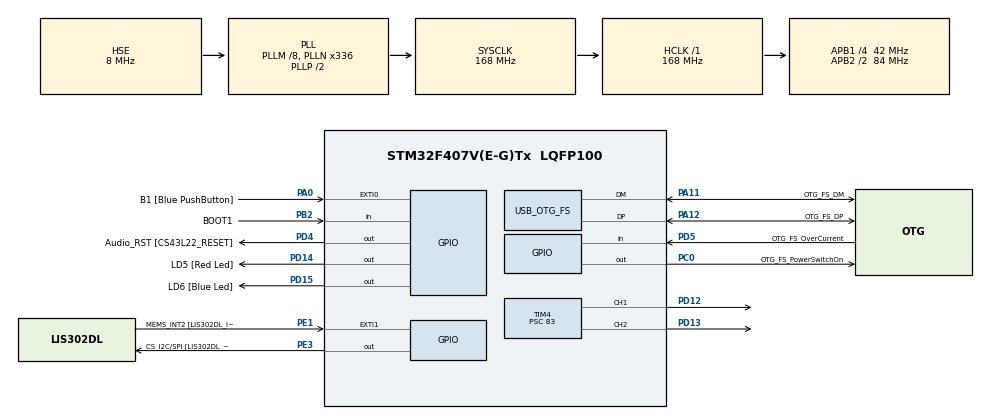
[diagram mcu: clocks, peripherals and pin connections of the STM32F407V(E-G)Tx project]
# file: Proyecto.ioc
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ADC1.Channel-0\#ChannelRegularConversion=ADC_CHANNEL_TEMPSENSOR
ADC1.NbrOfConversionFlag=1
ADC1.Rank-0\#ChannelRegularConversion=1
ADC1.SamplingTime-0\#ChannelRegularConversion=ADC_SAMPLETIME_3CYCLES
ADC1.master=1
Mcu.Family=STM32F4
Mcu.Name=STM32F407V(E-G)Tx
Mcu.Package=LQFP100
NVIC.EXTI0_IRQn=true\:0\:2\:false\:false\:true\:true\:true\:true
NVIC.OTG_FS_IRQn=true\:0\:0\:false\:false\:true\:false\:true\:true
NVIC.PriorityGroup=NVIC_PRIORITYGROUP_0
NVIC.TIM2_IRQn=true\:0\:1\:true\:false\:true\:true\:true\:true
PA0-WKUP.GPIO_Label=B1 [Blue PushButton]
PA0-WKUP.GPIO_ModeDefaultEXTI=GPIO_MODE_IT_RISING
PA0-WKUP.GPIO_PuPd=GPIO_NOPULL
PA0-WKUP.Signal=GPXTI0
PA10.GPIO_Label=OTG_FS_ID
PA10.GPIO_Mode=GPIO_MODE_AF_PP
PA10.GPIO_PuPd=GPIO_NOPULL
PA10.GPIO_Speed=GPIO_SPEED_FREQ_LOW
PA10.Signal=USB_OTG_FS_ID
PA11.GPIO_Label=OTG_FS_DM
PA11.GPIO_Mode=GPIO_MODE_AF_PP
PA11.GPIO_PuPd=GPIO_NOPULL
PA11.GPIO_Speed=GPIO_SPEED_FREQ_LOW
PA11.Mode=Device_Only
PA11.Signal=USB_OTG_FS_DM
PA12.GPIO_Label=OTG_FS_DP
PA12.GPIO_Mode=GPIO_MODE_AF_PP
PA12.GPIO_PuPd=GPIO_NOPULL
PA12.GPIO_Speed=GPIO_SPEED_FREQ_LOW
PA12.Mode=Device_Only
PA12.Signal=USB_OTG_FS_DP
PA13.GPIO_Label=SWDIO
PA13.Mode=Serial_Wire
PA13.Signal=SYS_JTMS-SWDIO
PA14.GPIO_Label=SWCLK
PA14.Mode=Serial_Wire
PA14.Signal=SYS_JTCK-SWCLK
PA4.GPIO_Label=I2S3_WS [CS43L22_LRCK]
PA4.GPIO_Mode=GPIO_MODE_AF_PP
PA4.GPIO_PuPd=GPIO_NOPULL
PA4.GPIO_Speed=GPIO_SPEED_FREQ_LOW
PA4.Signal=I2S3_WS
PA5.GPIO_Label=SPI1_SCK [LIS302DL_SCL/SPC]
PA5.GPIO_Mode=GPIO_MODE_AF_PP
PA5.GPIO_PuPd=GPIO_NOPULL
PA5.GPIO_Speed=GPIO_SPEED_FREQ_LOW
PA5.Signal=SPI1_SCK
PA6.GPIO_Label=SPI1_MISO [LIS302DL_SDO]
PA6.GPIO_Mode=GPIO_MODE_AF_PP
PA6.GPIO_PuPd=GPIO_NOPULL
PA6.GPIO_Speed=GPIO_SPEED_FREQ_LOW
PA6.Signal=SPI1_MISO
PA7.GPIO_Label=SPI1_MOSI [LIS302DL_SDA/SDI/SDO]
PA7.GPIO_Mode=GPIO_MODE_AF_PP
PA7.GPIO_PuPd=GPIO_NOPULL
PA7.GPIO_Speed=GPIO_SPEED_FREQ_LOW
PA7.Signal=SPI1_MOSI
PA9.GPIO_Label=VBUS_FS
PA9.GPIO_Mode=GPIO_MODE_INPUT
PA9.GPIO_PuPd=GPIO_NOPULL
PA9.Signal=USB_OTG_FS_VBUS
PB10.GPIO_Label=CLK_IN [MP45DT02_CLK]
PB10.GPIO_Mode=GPIO_MODE_AF_PP
PB10.GPIO_PuPd=GPIO_NOPULL
PB10.GPIO_Speed=GPIO_SPEED_FREQ_LOW
PB10.Signal=I2S2_CK
PB2.GPIO_Label=BOOT1
PB2.GPIO_Mode=GPIO_MODE_INPUT
PB2.GPIO_PuPd=GPIO_NOPULL
PB2.Signal=GPIO_Input
PB3.GPIO_Label=SWO
PB3.Signal=SYS_JTDO-SWO
PB6.GPIO_Label=Audio_SCL [CS43L22_SCL]
PB6.GPIO_Mode=GPIO_MODE_AF_OD
PB6.GPIO_Pu=GPIO_PULLUP
PB6.GPIO_PuPd=GPIO_NOPULL
PB6.GPIO_Speed=GPIO_SPEED_FREQ_LOW
PB6.Signal=I2C1_SCL
PB9.GPIO_Label=Audio_SDA [CS43L22_SDA]
PB9.GPIO_Mode=GPIO_MODE_AF_OD
PB9.GPIO_Pu=GPIO_PULLUP
PB9.GPIO_PuPd=GPIO_NOPULL
PB9.GPIO_Speed=GPIO_SPEED_FREQ_LOW
PB9.Signal=I2C1_SDA
PC0.GPIO_Label=OTG_FS_PowerSwitchOn
PC0.GPIO_PuPd=GPIO_NOPULL
PC0.GPIO_Speed=GPIO_SPEED_FREQ_LOW
PC0.PinState=GPIO_PIN_SET
PC0.Signal=GPIO_Output
PC10.GPIO_Label=I2S3_SCK [CS43L22_SCLK]
PC10.GPIO_Mode=GPIO_MODE_AF_PP
PC10.GPIO_PuPd=GPIO_NOPULL
PC10.GPIO_Speed=GPIO_SPEED_FREQ_LOW
PC10.Signal=I2S3_CK
PC12.GPIO_Label=I2S3_SD [CS43L22_SDIN]
PC12.GPIO_Mode=GPIO_MODE_AF_PP
PC12.GPIO_PuPd=GPIO_NOPULL
PC12.GPIO_Speed=GPIO_SPEED_FREQ_LOW
PC12.Signal=I2S3_SD
PC14-OSC32_IN.GPIO_Label=PC14-OSC32_IN
PC14-OSC32_IN.Mode=LSE-External-Oscillator
PC14-OSC32_IN.Signal=RCC_OSC32_IN
PC15-OSC32_OUT.GPIO_Label=PC15-OSC32_OUT
PC15-OSC32_OUT.Mode=LSE-External-Oscillator
PC15-OSC32_OUT.Signal=RCC_OSC32_OUT
PC3.GPIO_Label=PDM_OUT [MP45DT02_DOUT]
PC3.GPIO_Mode=GPIO_MODE_AF_PP
PC3.GPIO_PuPd=GPIO_NOPULL
PC3.GPIO_Speed=GPIO_SPEED_FREQ_LOW
PC3.Signal=I2S2_SD
PC7.GPIO_Label=I2S3_MCK [CS43L22_MCLK]
PC7.GPIO_Mode=GPIO_MODE_AF_PP
PC7.GPIO_PuPd=GPIO_NOPULL
PC7.GPIO_Speed=GPIO_SPEED_FREQ_LOW
PC7.Signal=I2S3_MCK
PD12.Signal=S_TIM4_CH1
PD13.Signal=S_TIM4_CH2
PD14.GPIO_Label=LD5 [Red Led]
PD14.GPIO_PuPd=GPIO_NOPULL
PD14.GPIO_Speed=GPIO_SPEED_FREQ_LOW
PD14.Signal=GPIO_Output
PD15.GPIO_Label=LD6 [Blue Led]
PD15.GPIO_PuPd=GPIO_NOPULL
PD15.GPIO_Speed=GPIO_SPEED_FREQ_LOW
PD15.Signal=GPIO_Output
PD4.GPIO_Label=Audio_RST [CS43L22_RESET]
PD4.GPIO_PuPd=GPIO_NOPULL
PD4.GPIO_Speed=GPIO_SPEED_FREQ_LOW
PD4.Signal=GPIO_Output
PD5.GPIO_Label=OTG_FS_OverCurrent
PD5.GPIO_Mode=GPIO_MODE_INPUT
PD5.GPIO_PuPd=GPIO_NOPULL
PD5.Signal=GPIO_Input
PE1.GPIO_Label=MEMS_INT2 [LIS302DL_INT2]
PE1.GPIO_ModeDefaultEXTI=GPIO_MODE_EVT_RISING
PE1.GPIO_PuPd=GPIO_NOPULL
PE1.Signal=GPXTI1
PE3.GPIO_Label=CS_I2C/SPI [LIS302DL_CS_I2C/SPI]
PE3.GPIO_PuPd=GPIO_NOPULL
PE3.GPIO_Speed=GPIO_SPEED_FREQ_LOW
PE3.Signal=GPIO_Output
PH0-OSC_IN.GPIO_Label=PH0-OSC_IN
PH0-OSC_IN.Mode=HSE-External-Oscillator
PH0-OSC_IN.Signal=RCC_OSC_IN
PH1-OSC_OUT.GPIO_Label=PH1-OSC_OUT
PH1-OSC_OUT.Mode=HSE-External-Oscillator
PH1-OSC_OUT.Signal=RCC_OSC_OUT
ProjectManager.HeapSize=0x200
ProjectManager.StackSize=0x400
ProjectManager.TargetToolchain=STM32CubeIDE
RCC.48MHZClocksFreq_Value=48000000
RCC.AHBFreq_Value=168000000
RCC.APB1CLKDivider=RCC_HCLK_DIV4
RCC.APB1Freq_Value=42000000
RCC.APB1TimFreq_Value=84000000
RCC.APB2CLKDivider=RCC_HCLK_DIV2
RCC.APB2Freq_Value=84000000
RCC.APB2TimFreq_Value=168000000
RCC.CortexFreq_Value=168000000
RCC.HCLKFreq_Value=168000000
RCC.HSE_VALUE=8000000
RCC.HSI_VALUE=16000000
RCC.PLLM=8
RCC.PLLN=336
RCC.PLLQ=7
RCC.SYSCLKFreq_VALUE=168000000
RCC.SYSCLKSource=RCC_SYSCLKSOURCE_PLLCLK
RCC.VCOOutputFreq_Value=336000000
SH.S_TIM4_CH1.0=TIM4_CH1,PWM Generation1 CH1
SH.S_TIM4_CH2.0=TIM4_CH2,PWM Generation2 CH2
TIM2.Period=99
TIM2.Prescaler=8399
TIM4.Channel-PWM\ Generation1\ CH1=TIM_CHANNEL_1
TIM4.Channel-PWM\ Generation2\ CH2=TIM_CHANNEL_2
TIM4.Period=999
TIM4.Prescaler=83
USB_DEVICE.CLASS_NAME_FS=CDC
USB_DEVICE.VirtualMode-CDC_FS=Cdc
USB_DEVICE.VirtualModeFS=Cdc_FS
USB_OTG_FS.VirtualMode=Device_Only
VP_ADC1_TempSens_Input.Mode=IN-TempSens
VP_TIM2_VS_ClockSourceINT.Mode=Internal
VP_TIM4_VS_ClockSourceINT.Mode=Internal
VP_USB_DEVICE_VS_USB_DEVICE_CDC_FS.Mode=CDC_FS
board=STM32F407G-DISC1

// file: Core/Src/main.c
/* USER CODE BEGIN Header */
/**
  ******************************************************************************
  * @file           : main.c
  * @brief          : Main program body
  ******************************************************************************
  * @attention
  *
  * Copyright (c) 2026 STMicroelectronics.
  * All rights reserved.
  *
  * This software is licensed under terms that can be found in the LICENSE file
  * in the root directory of this software component.
  * If no LICENSE file comes with this software, it is provided AS-IS.
  *
  ******************************************************************************
  */
/* USER CODE END Header */
#include "main.h"
#include "usb_device.h"
#include "usbd_cdc_if.h"
#include "bottler.h"

void MaquinaEstados(void);

ADC_HandleTypeDef hadc1;

TIM_HandleTypeDef htim2;
TIM_HandleTypeDef htim4;

void SystemClock_Config(void);
static void MX_GPIO_Init(void);
static void MX_TIM2_Init(void);
static void MX_TIM4_Init(void);
static void MX_ADC1_Init(void);

/* USER CODE BEGIN 0 */
volatile uint8_t presencia = 0;
volatile uint8_t contador = 0;
volatile uint8_t emergencia=0;
volatile uint8_t turno_usb=0; //0 envia temperatura y 1 envia estado
extern volatile uint8_t estado_anterior;
volatile uint32_t ultimo_envio = 0;
extern volatile uint8_t estado;
extern volatile float temp_actual;

/* USER CODE END 0 */

int main(void)
{

  /* USER CODE BEGIN 1 */
//  Definimso el comienzo //

  /* USER CODE END 1 */

  /* MCU Configuration--------------------------------------------------------*/

  /* Reset of all peripherals, Initializes the Flash interface and the Systick. */
  HAL_Init();

  /* Configure the system clock */
  SystemClock_Config();

  /* Initialize all configured peripherals */
  MX_GPIO_Init();
  MX_TIM2_Init();
  MX_TIM4_Init();
  MX_USB_DEVICE_Init();
  MX_ADC1_Init();
  /* USER CODE BEGIN 2 */
  bottlerInit();

  HAL_TIM_Base_Start_IT(&htim2);

  /* USER CODE END 2 */

  /* Infinite loop */
  while (1)
  {
	  MaquinaEstados();

		if ((turno_usb==0)&&(HAL_GetTick() - ultimo_envio > 100)) { //Comprobamos que haya pasado medio segundo desde el ultimo envio
		    temp_actual = getTemperature();

		    int ent = (int)temp_actual;
		    int dec = (int)((temp_actual - ent) * 10);
		    //Como la placa no trae activado el %f por defecto para ganar memoria, obtenemos las unidades y decimales cono enteros.
	        // obtenemos las unidades y decimales tratándolos matemáticamente como enteros.

		    char msg_temp[20];
		    sprintf(msg_temp, "T:%d.%d\r\n", ent, dec);
		    //Formateamos una cadena de caracteres como T:(ent).(dec)\r\n
		    //Añadimos \r\n (salto de línea) al final para que el SCADA en Qt sepa exactamente dónde termina el mensaje al usar readLine().
		    CDC_Transmit_FS((uint8_t*)msg_temp, strlen(msg_temp)); //Transmitimos la cadena de texto a la interfaz.

		    turno_usb=0;

		    ultimo_envio = HAL_GetTick(); //Obtenemos el momento en el que se ha realizado el ultimo envío.
		    //HAL_GetTick() es una funcion que nos dice cuanto tiempo ha estado encendido el Stm32.

		}

		if ((turno_usb==1)&&(HAL_GetTick() - ultimo_envio > 100)) { //Comprobamos que haya pasado medio segundo desde el ultimo envio

			//Forzamos el envío del estado actual de forma periódica así nuestra interfaz se entera del estado real aunque arranque tarde.
			char msg_est[20];//Declaramos y definimos una cadena de caracteres vacia que se reseteará cada vez que el superloop llame a la maquina de estados.
			sprintf(msg_est, "%d\r\n", estado); //Escribimos nuestro estado por encima de los caracteres vacios de la cadena.
			CDC_Transmit_FS((uint8_t*)msg_est, strlen(msg_est));//Transmitimos la cadena de texto a la interfaz.
			//Un problema que teniamos es que si arrancabamos la interfaz un rato despues del programa se quedaba colgada en el estado 0
			//Aunque estuviese por ejemplo en emergencia hasta que cambiaba de estado, metiendo esta actualizacion periodica siempre sabremos donde esta.

			turno_usb=0;

			ultimo_envio = HAL_GetTick(); //Obtenemos el momento en el que se ha realizado el ultimo envío.
			//HAL_GetTick() es una funcion que nos dice cuanto tiempo ha estado encendido el Stm32.
		}

  }
}

void SystemClock_Config(void)
{
  RCC_OscInitTypeDef RCC_OscInitStruct = {0};
  RCC_ClkInitTypeDef RCC_ClkInitStruct = {0};

  /** Configure the main internal regulator output voltage
  */
  __HAL_RCC_PWR_CLK_ENABLE();
  __HAL_PWR_VOLTAGESCALING_CONFIG(PWR_REGULATOR_VOLTAGE_SCALE1);

  /** Initializes the RCC Oscillators according to the specified parameters
  * in the RCC_OscInitTypeDef structure.
  */
  RCC_OscInitStruct.OscillatorType = RCC_OSCILLATORTYPE_HSE;
  RCC_OscInitStruct.HSEState = RCC_HSE_ON;
  RCC_OscInitStruct.PLL.PLLState = RCC_PLL_ON;
  RCC_OscInitStruct.PLL.PLLSource = RCC_PLLSOURCE_HSE;
  RCC_OscInitStruct.PLL.PLLM = 8;
  RCC_OscInitStruct.PLL.PLLN = 336;
  RCC_OscInitStruct.PLL.PLLP = RCC_PLLP_DIV2;
  RCC_OscInitStruct.PLL.PLLQ = 7;
  if (HAL_RCC_OscConfig(&RCC_OscInitStruct) != HAL_OK)
  {
    Error_Handler();
  }

  /** Initializes the CPU, AHB and APB buses clocks
  */
  RCC_ClkInitStruct.ClockType = RCC_CLOCKTYPE_HCLK|RCC_CLOCKTYPE_SYSCLK
                              |RCC_CLOCKTYPE_PCLK1|RCC_CLOCKTYPE_PCLK2;
  RCC_ClkInitStruct.SYSCLKSource = RCC_SYSCLKSOURCE_PLLCLK;
  RCC_ClkInitStruct.AHBCLKDivider = RCC_SYSCLK_DIV1;
  RCC_ClkInitStruct.APB1CLKDivider = RCC_HCLK_DIV4;
  RCC_ClkInitStruct.APB2CLKDivider = RCC_HCLK_DIV2;

  if (HAL_RCC_ClockConfig(&RCC_ClkInitStruct, FLASH_LATENCY_5) != HAL_OK)
  {
    Error_Handler();
  }
}

static void MX_ADC1_Init(void)
{

  ADC_ChannelConfTypeDef sConfig = {0};

  /** Configure the global features of the ADC (Clock, Resolution, Data Alignment and number of conversion)
  */
  hadc1.Instance = ADC1;
  hadc1.Init.ClockPrescaler = ADC_CLOCK_SYNC_PCLK_DIV4;
  hadc1.Init.Resolution = ADC_RESOLUTION_12B;
  hadc1.Init.ScanConvMode = DISABLE;
  hadc1.Init.ContinuousConvMode = DISABLE;
  hadc1.Init.DiscontinuousConvMode = DISABLE;
  hadc1.Init.ExternalTrigConvEdge = ADC_EXTERNALTRIGCONVEDGE_NONE;
  hadc1.Init.ExternalTrigConv = ADC_SOFTWARE_START;
  hadc1.Init.DataAlign = ADC_DATAALIGN_RIGHT;
  hadc1.Init.NbrOfConversion = 1;
  hadc1.Init.DMAContinuousRequests = DISABLE;
  hadc1.Init.EOCSelection = ADC_EOC_SINGLE_CONV;
  if (HAL_ADC_Init(&hadc1) != HAL_OK)
  {
    Error_Handler();
  }

  /** Configure for the selected ADC regular channel its corresponding rank in the sequencer and its sample time.
  */
  sConfig.Channel = ADC_CHANNEL_TEMPSENSOR;
  sConfig.Rank = 1;
  sConfig.SamplingTime = ADC_SAMPLETIME_3CYCLES;
  if (HAL_ADC_ConfigChannel(&hadc1, &sConfig) != HAL_OK)
  {
    Error_Handler();
  }

}

static void MX_TIM2_Init(void)
{

  TIM_ClockConfigTypeDef sClockSourceConfig = {0};
  TIM_MasterConfigTypeDef sMasterConfig = {0};

  htim2.Instance = TIM2;
  htim2.Init.Prescaler = 8399;
  htim2.Init.CounterMode = TIM_COUNTERMODE_UP;
  htim2.Init.Period = 99;
  htim2.Init.ClockDivision = TIM_CLOCKDIVISION_DIV1;
  htim2.Init.AutoReloadPreload = TIM_AUTORELOAD_PRELOAD_DISABLE;
  if (HAL_TIM_Base_Init(&htim2) != HAL_OK)
  {
    Error_Handler();
  }
  sClockSourceConfig.ClockSource = TIM_CLOCKSOURCE_INTERNAL;
  if (HAL_TIM_ConfigClockSource(&htim2, &sClockSourceConfig) != HAL_OK)
  {
    Error_Handler();
  }
  sMasterConfig.MasterOutputTrigger = TIM_TRGO_RESET;
  sMasterConfig.MasterSlaveMode = TIM_MASTERSLAVEMODE_DISABLE;
  if (HAL_TIMEx_MasterConfigSynchronization(&htim2, &sMasterConfig) != HAL_OK)
  {
    Error_Handler();
  }

}

static void MX_TIM4_Init(void)
{

  TIM_ClockConfigTypeDef sClockSourceConfig = {0};
  TIM_MasterConfigTypeDef sMasterConfig = {0};
  TIM_OC_InitTypeDef sConfigOC = {0};

  htim4.Instance = TIM4;
  htim4.Init.Prescaler = 83;
  htim4.Init.CounterMode = TIM_COUNTERMODE_UP;
  htim4.Init.Period = 999;
  htim4.Init.ClockDivision = TIM_CLOCKDIVISION_DIV1;
  htim4.Init.AutoReloadPreload = TIM_AUTORELOAD_PRELOAD_DISABLE;
  if (HAL_TIM_Base_Init(&htim4) != HAL_OK)
  {
    Error_Handler();
  }
  sClockSourceConfig.ClockSource = TIM_CLOCKSOURCE_INTERNAL;
  if (HAL_TIM_ConfigClockSource(&htim4, &sClockSourceConfig) != HAL_OK)
  {
    Error_Handler();
  }
  if (HAL_TIM_PWM_Init(&htim4) != HAL_OK)
  {
    Error_Handler();
  }
  sMasterConfig.MasterOutputTrigger = TIM_TRGO_RESET;
  sMasterConfig.MasterSlaveMode = TIM_MASTERSLAVEMODE_DISABLE;
  if (HAL_TIMEx_MasterConfigSynchronization(&htim4, &sMasterConfig) != HAL_OK)
  {
    Error_Handler();
  }
  sConfigOC.OCMode = TIM_OCMODE_PWM1;
  sConfigOC.Pulse = 0;
  sConfigOC.OCPolarity = TIM_OCPOLARITY_HIGH;
  sConfigOC.OCFastMode = TIM_OCFAST_DISABLE;
  if (HAL_TIM_PWM_ConfigChannel(&htim4, &sConfigOC, TIM_CHANNEL_1) != HAL_OK)
  {
    Error_Handler();
  }
  if (HAL_TIM_PWM_ConfigChannel(&htim4, &sConfigOC, TIM_CHANNEL_2) != HAL_OK)
  {
    Error_Handler();
  }
  HAL_TIM_MspPostInit(&htim4);

}

static void MX_GPIO_Init(void)
{
  GPIO_InitTypeDef GPIO_InitStruct = {0};

  /* GPIO Ports Clock Enable */
  __HAL_RCC_GPIOE_CLK_ENABLE();
  __HAL_RCC_GPIOC_CLK_ENABLE();
  __HAL_RCC_GPIOH_CLK_ENABLE();
  __HAL_RCC_GPIOA_CLK_ENABLE();
  __HAL_RCC_GPIOB_CLK_ENABLE();
  __HAL_RCC_GPIOD_CLK_ENABLE();

  /*Configure GPIO pin Output Level */
  HAL_GPIO_WritePin(CS_I2C_SPI_GPIO_Port, CS_I2C_SPI_Pin, GPIO_PIN_RESET);

  /*Configure GPIO pin Output Level */
  HAL_GPIO_WritePin(OTG_FS_PowerSwitchOn_GPIO_Port, OTG_FS_PowerSwitchOn_Pin, GPIO_PIN_SET);

  /*Configure GPIO pin Output Level */
  HAL_GPIO_WritePin(GPIOD, LD5_Pin|LD6_Pin|Audio_RST_Pin, GPIO_PIN_RESET);

  /*Configure GPIO pin : CS_I2C_SPI_Pin */
  GPIO_InitStruct.Pin = CS_I2C_SPI_Pin;
  GPIO_InitStruct.Mode = GPIO_MODE_OUTPUT_PP;
  GPIO_InitStruct.Pull = GPIO_NOPULL;
  GPIO_InitStruct.Speed = GPIO_SPEED_FREQ_LOW;
  HAL_GPIO_Init(CS_I2C_SPI_GPIO_Port, &GPIO_InitStruct);

  /*Configure GPIO pin : OTG_FS_PowerSwitchOn_Pin */
  GPIO_InitStruct.Pin = OTG_FS_PowerSwitchOn_Pin;
  GPIO_InitStruct.Mode = GPIO_MODE_OUTPUT_PP;
  GPIO_InitStruct.Pull = GPIO_NOPULL;
  GPIO_InitStruct.Speed = GPIO_SPEED_FREQ_LOW;
  HAL_GPIO_Init(OTG_FS_PowerSwitchOn_GPIO_Port, &GPIO_InitStruct);

  /*Configure GPIO pin : PDM_OUT_Pin */
  GPIO_InitStruct.Pin = PDM_OUT_Pin;
  GPIO_InitStruct.Mode = GPIO_MODE_AF_PP;
  GPIO_InitStruct.Pull = GPIO_NOPULL;
  GPIO_InitStruct.Speed = GPIO_SPEED_FREQ_LOW;
  GPIO_InitStruct.Alternate = GPIO_AF5_SPI2;
  HAL_GPIO_Init(PDM_OUT_GPIO_Port, &GPIO_InitStruct);

  /*Configure GPIO pin : B1_Pin */
  GPIO_InitStruct.Pin = B1_Pin;
  GPIO_InitStruct.Mode = GPIO_MODE_IT_RISING;
  GPIO_InitStruct.Pull = GPIO_NOPULL;
  HAL_GPIO_Init(B1_GPIO_Port, &GPIO_InitStruct);

  /*Configure GPIO pin : I2S3_WS_Pin */
  GPIO_InitStruct.Pin = I2S3_WS_Pin;
  GPIO_InitStruct.Mode = GPIO_MODE_AF_PP;
  GPIO_InitStruct.Pull = GPIO_NOPULL;
  GPIO_InitStruct.Speed = GPIO_SPEED_FREQ_LOW;
  GPIO_InitStruct.Alternate = GPIO_AF6_SPI3;
  HAL_GPIO_Init(I2S3_WS_GPIO_Port, &GPIO_InitStruct);

  /*Configure GPIO pins : SPI1_SCK_Pin SPI1_MISO_Pin SPI1_MOSI_Pin */
  GPIO_InitStruct.Pin = SPI1_SCK_Pin|SPI1_MISO_Pin|SPI1_MOSI_Pin;
  GPIO_InitStruct.Mode = GPIO_MODE_AF_PP;
  GPIO_InitStruct.Pull = GPIO_NOPULL;
  GPIO_InitStruct.Speed = GPIO_SPEED_FREQ_LOW;
  GPIO_InitStruct.Alternate = GPIO_AF5_SPI1;
  HAL_GPIO_Init(GPIOA, &GPIO_InitStruct);

  /*Configure GPIO pin : BOOT1_Pin */
  GPIO_InitStruct.Pin = BOOT1_Pin;
  GPIO_InitStruct.Mode = GPIO_MODE_INPUT;
  GPIO_InitStruct.Pull = GPIO_NOPULL;
  HAL_GPIO_Init(BOOT1_GPIO_Port, &GPIO_InitStruct);

  /*Configure GPIO pin : CLK_IN_Pin */
  GPIO_InitStruct.Pin = CLK_IN_Pin;
  GPIO_InitStruct.Mode = GPIO_MODE_AF_PP;
  GPIO_InitStruct.Pull = GPIO_NOPULL;
  GPIO_InitStruct.Speed = GPIO_SPEED_FREQ_LOW;
  GPIO_InitStruct.Alternate = GPIO_AF5_SPI2;
  HAL_GPIO_Init(CLK_IN_GPIO_Port, &GPIO_InitStruct);

  /*Configure GPIO pins : LD5_Pin LD6_Pin Audio_RST_Pin */
  GPIO_InitStruct.Pin = LD5_Pin|LD6_Pin|Audio_RST_Pin;
  GPIO_InitStruct.Mode = GPIO_MODE_OUTPUT_PP;
  GPIO_InitStruct.Pull = GPIO_NOPULL;
  GPIO_InitStruct.Speed = GPIO_SPEED_FREQ_LOW;
  HAL_GPIO_Init(GPIOD, &GPIO_InitStruct);

  /*Configure GPIO pins : I2S3_MCK_Pin I2S3_SCK_Pin I2S3_SD_Pin */
  GPIO_InitStruct.Pin = I2S3_MCK_Pin|I2S3_SCK_Pin|I2S3_SD_Pin;
  GPIO_InitStruct.Mode = GPIO_MODE_AF_PP;
  GPIO_InitStruct.Pull = GPIO_NOPULL;
  GPIO_InitStruct.Speed = GPIO_SPEED_FREQ_LOW;
  GPIO_InitStruct.Alternate = GPIO_AF6_SPI3;
  HAL_GPIO_Init(GPIOC, &GPIO_InitStruct);

  /*Configure GPIO pin : OTG_FS_OverCurrent_Pin */
  GPIO_InitStruct.Pin = OTG_FS_OverCurrent_Pin;
  GPIO_InitStruct.Mode = GPIO_MODE_INPUT;
  GPIO_InitStruct.Pull = GPIO_NOPULL;
  HAL_GPIO_Init(OTG_FS_OverCurrent_GPIO_Port, &GPIO_InitStruct);

  /*Configure GPIO pins : Audio_SCL_Pin Audio_SDA_Pin */
  GPIO_InitStruct.Pin = Audio_SCL_Pin|Audio_SDA_Pin;
  GPIO_InitStruct.Mode = GPIO_MODE_AF_OD;
  GPIO_InitStruct.Pull = GPIO_PULLUP;
  GPIO_InitStruct.Speed = GPIO_SPEED_FREQ_LOW;
  GPIO_InitStruct.Alternate = GPIO_AF4_I2C1;
  HAL_GPIO_Init(GPIOB, &GPIO_InitStruct);

  /*Configure GPIO pin : MEMS_INT2_Pin */
  GPIO_InitStruct.Pin = MEMS_INT2_Pin;
  GPIO_InitStruct.Mode = GPIO_MODE_EVT_RISING;
  GPIO_InitStruct.Pull = GPIO_NOPULL;
  HAL_GPIO_Init(MEMS_INT2_GPIO_Port, &GPIO_InitStruct);

  /* EXTI interrupt init*/
  HAL_NVIC_SetPriority(EXTI0_IRQn, 0, 2);
  HAL_NVIC_EnableIRQ(EXTI0_IRQn);

}

void Error_Handler(void)
{
  __disable_irq();
  while (1)
  {
  }
}
